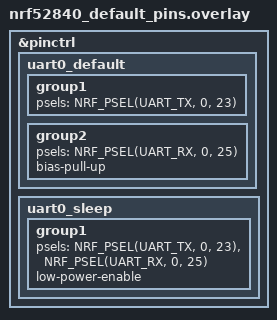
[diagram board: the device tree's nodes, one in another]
/*
 * MTIB REV 1.2 UART pin correction — nRF52840 (Alpha B0).
 *
 * Restores UART0 pin assignments to base DTS defaults after a pin-swap
 * overlay has been applied. Used for REV 1.2 manufacturing builds where
 * the submodule overlay bakes in REV 1.1 pin swap.
 *
 * Pins: TX=P0.23, RX=P0.25 (base DTS defaults)
 *
 * Apply via: -DDTC_OVERLAY_FILE="<submodule_overlay>;overlays/nrf52840_default_pins.overlay"
 */

&pinctrl {
    uart0_default: uart0_default {
        group1 {
            psels = <NRF_PSEL(UART_TX, 0, 23)>;
        };
        group2 {
            psels = <NRF_PSEL(UART_RX, 0, 25)>;
            bias-pull-up;
        };
    };

    uart0_sleep: uart0_sleep {
        group1 {
            psels = <NRF_PSEL(UART_TX, 0, 23)>,
                    <NRF_PSEL(UART_RX, 0, 25)>;
            low-power-enable;
        };
    };
};
